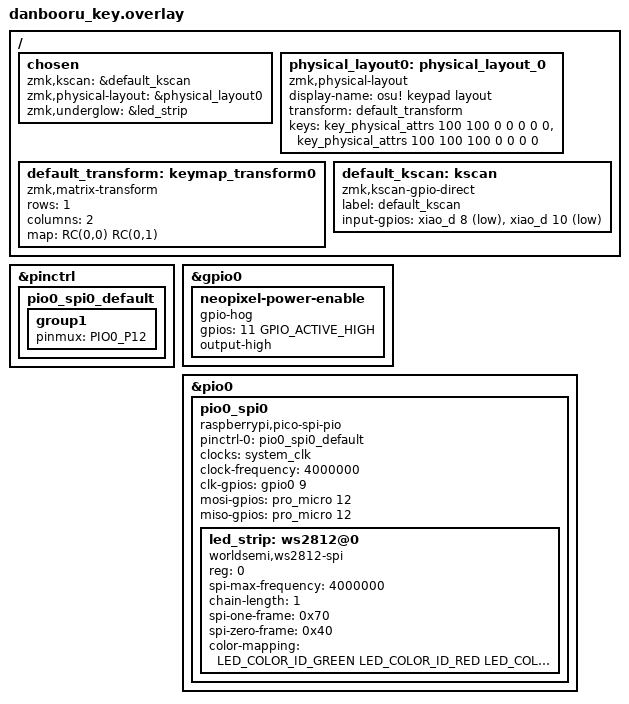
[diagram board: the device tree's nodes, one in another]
#include <dt-bindings/zmk/matrix_transform.h>
#include <physical_layouts.dtsi>
#include <dt-bindings/pinctrl/rpi-pico-rp2040-pinctrl.h>
#include <dt-bindings/led/led.h>

/ {
  chosen {
    zmk,kscan = &default_kscan;
    zmk,physical-layout = &physical_layout0;
    zmk,underglow = &led_strip;
  };

  physical_layout0: physical_layout_0 {
    compatible = "zmk,physical-layout";
    display-name = "osu! keypad layout";
    transform = <&default_transform>;
    keys  //                       w   h    x      y       rot    rx    ry
            = <&key_physical_attrs 100 100    0    0       0     0     0>
            , <&key_physical_attrs 100 100  100    0       0     0     0>
            ;
  };

  default_transform: keymap_transform0 {
    compatible = "zmk,matrix-transform";
    rows = <1>;
    columns = <2>;

    map = < RC(0,0) RC(0,1) >;
  };

  default_kscan: kscan {
    compatible = "zmk,kscan-gpio-direct";
    label = "default_kscan";  

    input-gpios =  
      <&xiao_d 8 (GPIO_ACTIVE_LOW | GPIO_PULL_UP)>,
      <&xiao_d 10 (GPIO_ACTIVE_LOW | GPIO_PULL_UP)>;
  };
};

&pinctrl {
  pio0_spi0_default: pio0_spi0_default {
    group1 {
        pinmux = <PIO0_P12>;
    };
  };
};

&gpio0 {
     status = "okay";
     neopixel-power-enable {
  gpio-hog;
  gpios = <11 GPIO_ACTIVE_HIGH>;
  output-high;
 };
};

&pio0 {
  status = "okay";

  pio0_spi0: pio0_spi0 {
    pinctrl-0 = <&pio0_spi0_default>;
    pinctrl-names = "default";

    compatible = "raspberrypi,pico-spi-pio";
    #address-cells = <1>;
    #size-cells = <0>;
    clocks = <&system_clk>;
    clock-frequency = <4000000>;

    clk-gpios = <&gpio0 9 GPIO_ACTIVE_HIGH>;     /* Must be defined. Select a pin that is not used elsewhere. */
    mosi-gpios = <&pro_micro 12 GPIO_ACTIVE_HIGH>; /* Data In pin. */
    miso-gpios = <&pro_micro 12 GPIO_ACTIVE_HIGH>; /* Must be defined. Re-using the DI pin is OK for WS2812. */

    led_strip: ws2812@0 {
      compatible = "worldsemi,ws2812-spi";

      /* SPI */
      reg = <0>; /* ignored, but necessary for SPI bindings */
      spi-max-frequency = <4000000>;

      /* WS2812 */
      chain-length = <1>; /* number of LEDs */
      spi-one-frame = <0x70>;
      spi-zero-frame = <0x40>;
      color-mapping = <LED_COLOR_ID_GREEN
                        LED_COLOR_ID_RED
                        LED_COLOR_ID_BLUE>;
    };
  };  
};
